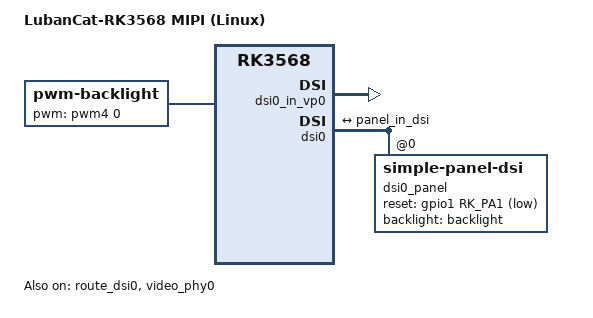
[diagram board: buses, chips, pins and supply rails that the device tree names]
// SPDX-License-Identifier: (GPL-2.0+ OR MIT)
/*
 * Copyright (c) 2020 Rockchip Electronics Co., Ltd.
 *
 */


#include "rk3568-lubancat-dev.dtsi"

/ {
    model = "LubanCat-RK3568 MIPI (Linux)";
    compatible = "rockchip,rk3568-lubancat-dev", "rockchip,rk3568";

    backlight: backlight {
	status = "okay";
	compatible = "pwm-backlight";
	pwms = <&pwm4 0 50000 0>;
	brightness-levels = <
		 95  95  95  95  95  95  95  95
		 95  95  95  95  95  95  95  95
		 95  95  95  95  95  95  95  95
		 95  95  95  95  95  95  95  95
		 95  95  95  95  95  95  95  95
		 95  95  95  95  95  95  95  95
		 95  95  95  95  95  95  95  95
		 95  95  95  95  95  95  95  95
		 95  95  95  95  95  95  95  95
		 95  95  95  95  95  95  95  95
		 95  95  95  95  95  95  95  95
		 88  89  90  91  92  93  94  95
		 96  97  98  99 100 101 102 103
		104 105 106 107 108 109 110 111
		112 113 114 115 116 117 118 119
		120 121 122 123 124 125 126 127
		128 129 130 131 132 133 134 135
		136 137 138 139 140 141 142 143
		144 145 146 147 148 149 150 151
		152 153 154 155 156 157 158 159
		160 161 162 163 164 165 166 167
		168 169 170 171 172 173 174 175
		176 177 178 179 180 181 182 183
		184 185 186 187 188 189 190 191
		192 193 194 195 196 197 198 199
		200 201 202 203 204 205 206 207
		208 209 210 211 212 213 214 215
		216 217 218 219 220 221 222 223
		224 225 226 227 228 229 230 231
		232 233 234 235 236 237 238 239
		240 241 242 243 244 245 246 247
		248 249 250 251 252 253 254 255
	>;
	default-brightness-level = <200>;
    };
};

&route_dsi0 {
	status = "okay";
	connect = <&vp0_out_dsi0>;
};

&video_phy0 {
	status = "okay";
};

&dsi0_in_vp0 {
    status = "okay";
};

&dsi0_in_vp1 {
    status = "disabled";
};


/*
 * video_phy0 needs to be enabled
 * when dsi0 is enabled
 */
&dsi0 {
	status = "okay";

	dsi0_panel: panel@0 {
		status = "okay";
		compatible = "simple-panel-dsi";
		reg = <0>;
		backlight = <&backlight>;
		reset-gpios = <&gpio1 RK_PA1 GPIO_ACTIVE_LOW>;
		reset-delay-ms = <20>;

		size,width = <68>;
		size,height = <121>;
		dsi,flags = <(MIPI_DSI_MODE_VIDEO | MIPI_DSI_MODE_VIDEO_BURST | MIPI_DSI_MODE_LPM | MIPI_DSI_    MODE_EOT_PACKET)>;
		dsi,format = <MIPI_DSI_FMT_RGB888>;
		dsi,lanes  = <4>;
		panel-init-sequence = [
		    15 00 04 FF 98 81 03
		    15 00 02 01 00
		    15 00 02 02 00
                    15 00 02 03 72
                    15 00 02 04 00
		    15 00 02 05 00
		    15 00 02 06 09
		    15 00 02 07 00
		    15 00 02 08 00
		    15 00 02 09 01
                    15 00 02 0A 00
	            15 00 02 0B 00
		    15 00 02 0C 01
		    15 00 02 0D 00
		    15 00 02 0E 00
		    15 00 02 0F 00
		    15 00 02 10 00
		    15 00 02 11 00
		    15 00 02 12 00
		    15 00 02 13 00
		    15 00 02 14 00
		    15 00 02 15 00
		    15 00 02 16 00
		    15 00 02 17 00
		    15 00 02 18 00
		    15 00 02 19 00
		    15 00 02 1a 00
		    15 00 02 1b 00
		    15 00 02 1c 00
		    15 00 02 1d 00
		    15 00 02 1e 40
		    15 00 02 1f 80
		    15 00 02 20 05
		    15 00 02 21 02
		    15 00 02 22 00
		    15 00 02 23 00
		    15 00 02 24 00
		    15 00 02 25 00
		    15 00 02 26 00
		    15 00 02 27 00
		    15 00 02 28 33
		    15 00 02 29 02
		    15 00 02 2a 00
		    15 00 02 2b 00
		    15 00 02 2c 00
		    15 00 02 2d 00
		    15 00 02 2e 00
		    15 00 02 2f 00
		    15 00 02 30 00
		    15 00 02 31 00
		    15 00 02 32 00
		    15 00 02 33 00
		    15 00 02 34 00
		    15 00 02 35 00
		    15 00 02 36 00
		    15 00 02 37 00
		    15 00 02 38 3C
		    15 00 02 39 00
		    15 00 02 3a 40
		    15 00 02 3b 40
		    15 00 02 3c 00
		    15 00 02 3d 00
		    15 00 02 3e 00
		    15 00 02 3f 00
		    15 00 02 40 00
		    15 00 02 41 00
		    15 00 02 42 00
		    15 00 02 43 00
		    15 00 02 44 00
		    15 00 02 50 00
		    15 00 02 51 23
		    15 00 02 52 45
		    15 00 02 53 67
		    15 00 02 54 89
		    15 00 02 55 ab
		    15 00 02 56 01
		    15 00 02 57 23
		    15 00 02 58 45
		    15 00 02 59 67
		    15 00 02 5a 89
		    15 00 02 5b ab
		    15 00 02 5c cd
		    15 00 02 5d ef
		    15 00 02 5e 11
		    15 00 02 5f 01
		    15 00 02 60 00
		    15 00 02 61 15
		    15 00 02 62 14
		    15 00 02 63 0e
		    15 00 02 64 0f
		    15 00 02 65 0c
		    15 00 02 66 0d
		    15 00 02 67 06
		    15 00 02 68 02
		    15 00 02 69 02
		    15 00 02 6a 02
		    15 00 02 6b 02
		    15 00 02 6c 02
		    15 00 02 6d 02
		    15 00 02 6e 07
		    15 00 02 6f 02
		    15 00 02 70 02
		    15 00 02 71 02
		    15 00 02 72 02
		    15 00 02 73 02
		    15 00 02 74 02
		    15 00 02 75 01
		    15 00 02 76 00
		    15 00 02 77 14
		    15 00 02 78 15
		    15 00 02 79 0e
		    15 00 02 7a 0f
		    15 00 02 7b 0c
		    15 00 02 7c 0d
		    15 00 02 7d 06
		    15 00 02 7e 02
		    15 00 02 7f 07
		    15 00 02 80 02
		    15 00 02 81 02
		    15 00 02 82 02
		    15 00 02 83 02
		    15 00 02 84 07
		    15 00 02 85 02
		    15 00 02 86 02
		    15 00 02 87 02
		    15 00 02 88 02
		    15 00 02 89 02
		    15 00 02 8a 02

		    15 00 04 ff 98 81 04
		    15 00 02 6c 15
		    15 00 02 6e 2a
		    15 00 02 6f 33
		    15 00 02 3a 94
		    15 00 02 8d 1a
		    15 00 02 87 ba
		    15 00 02 26 76
		    15 00 02 b2 d1
		    15 00 02 b5 06

		    15 00 04 ff 98 81 01
		    15 00 02 22 0a
		    15 00 02 31 00
		    15 00 02 53 8a
		    15 00 02 55 8a
		    15 00 02 50 ae
		    15 00 02 51 ae
		    15 00 02 60 28
		    15 00 02 61 00
		    15 00 02 62 19
		    15 00 02 63 10
		    15 00 02 a0 0f
		    15 00 02 a1 1b
		    15 00 02 a2 28
		    15 00 02 a3 12
		    15 00 02 a4 15
		    15 00 02 a5 28
		    15 00 02 a6 1b
		    15 00 02 a7 1e
		    15 00 02 a8 79
		    15 00 02 a9 1b
		    15 00 02 aa 27
		    15 00 02 ab 69
		    15 00 02 ac 19
		    15 00 02 ad 18
		    15 00 02 ae 4c
		    15 00 02 af 21
		    15 00 02 b0 28
		    15 00 02 b1 52
		    15 00 02 b2 65
		    15 00 02 b3 3f
		    15 00 02 c0 04
		    15 00 02 c1 1b
		    15 00 02 c0 27
		    15 00 02 c3 13
		    15 00 02 c4 15
		    15 00 02 c5 28
		    15 00 02 c6 1c
		    15 00 02 c7 1e
		    15 00 02 c8 79
		    15 00 02 c9 1a
		    15 00 02 ca 27
		    15 00 02 cb 69
		    15 00 02 cc 1a
		    15 00 02 cd 18
		    15 00 02 ce 4c
		    15 00 02 cf 21
	            15 00 02 d0 27
		    15 00 02 d1 52
		    15 00 02 d2 65
		    15 00 02 d3 3f

		    15 00 04 ff 98 81 00
		    15 00 02 35 00
		    15 00 02 3a 70
	            15 78 01 11
		    15 19 01 29
		];
	};

	ports {
		#address-cells = <1>;
		#size-cells = <0>;

		port@1 {
			reg = <1>;
			dsi_out_panel: endpoint {
				remote-endpoint = <&panel_in_dsi>;
			};
		};
	};
};

&hdmi {
	status = "disabled";
};
